# CY8C5888LTI_LP097 register map
File version: 0.1
CY8C58LP
Registers are 16-bit, read-write, no defined reset value unless marked. A register's access mark holds for its fields unless they carry their own. Offsets are from the block's base; lines under a group give offsets from that group; [hi:lo] are bit positions; {n}, {i} and the like mark numbered series; 'fields as' and 'values as' point back to an identical list; <NAME> marks a mode.

## Memory map
0x00000000 NSDSPI_RX_BYTE_COUNTER
0x00000000 NSDSPI_CTRL

## NSDSPI_RX_BYTE_COUNTER
Base 0x00000000
0x4000640A NSDSPI_RX_BYTE_COUNTER_COUNTER — UDB.A0 - Current Counter Value
0x4000642A NSDSPI_RX_BYTE_COUNTER_PERIOD — UDB.D0 - Assigned Period
0x4000643A NSDSPI_RX_BYTE_COUNTER_COMPARE — UDB.D1 - Assigned Compare Value
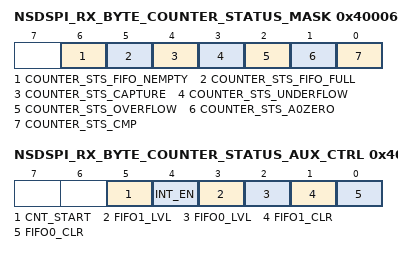
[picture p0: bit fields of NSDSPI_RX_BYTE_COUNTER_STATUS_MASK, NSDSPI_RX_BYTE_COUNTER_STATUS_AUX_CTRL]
0x4000648B NSDSPI_RX_BYTE_COUNTER_STATUS_MASK 8-bit — UDB Status bits Interrupt Mask Enable Register
  [6] COUNTER_STS_FIFO_NEMPTY — FIFO Not Empty Status
  [5] COUNTER_STS_FIFO_FULL — FIFO Full Status
  [4] COUNTER_STS_CAPTURE — Capture Status
  [3] COUNTER_STS_UNDERFLOW — Underflow status
  [2] COUNTER_STS_OVERFLOW — Overflow status
  [1] COUNTER_STS_A0ZERO — A0 Zero ouput status
  [0] COUNTER_STS_CMP — Compare output status
0x4000649B NSDSPI_RX_BYTE_COUNTER_STATUS_AUX_CTRL 8-bit — UDB Auxilliary Control Register
  [5] CNT_START — FIFO0 clear
    0=E_CNT_START0 (Disable counter); 1=E_CNT_START1 (Enable counter)
  [4] INT_EN
    0=E_INT_EN0 (Interrupt disabled); 1=E_INT_EN1 (Interrupt enabled)
  [3] FIFO1_LVL — FIFO level
    0=E_FIFO_LVL_0 (FIFO LVL: input mode: FIFO not full; output mode: FIFO not empty); 1=E_FIFO_LVL_1 (FIFO LVL: input mode: FIFO at least 1/2 empty; output mode: FIFO at least 1/2 full)
  [2] FIFO0_LVL — FIFO level
    values as FIFO1_LVL
  [1] FIFO1_CLR — FIFO1 clear
    0=E_FIFO_CLR_0 (Normal FIFO operation); 1=E_FIFO_CLR_1 (Clear FIFO state)
  [0] FIFO0_CLR — FIFO0 clear
    values as FIFO1_CLR

## NSDSPI_CTRL
Base 0x00000000
0x4000647B NSDSPI_CTRL_CONTROL_REG 8-bit
